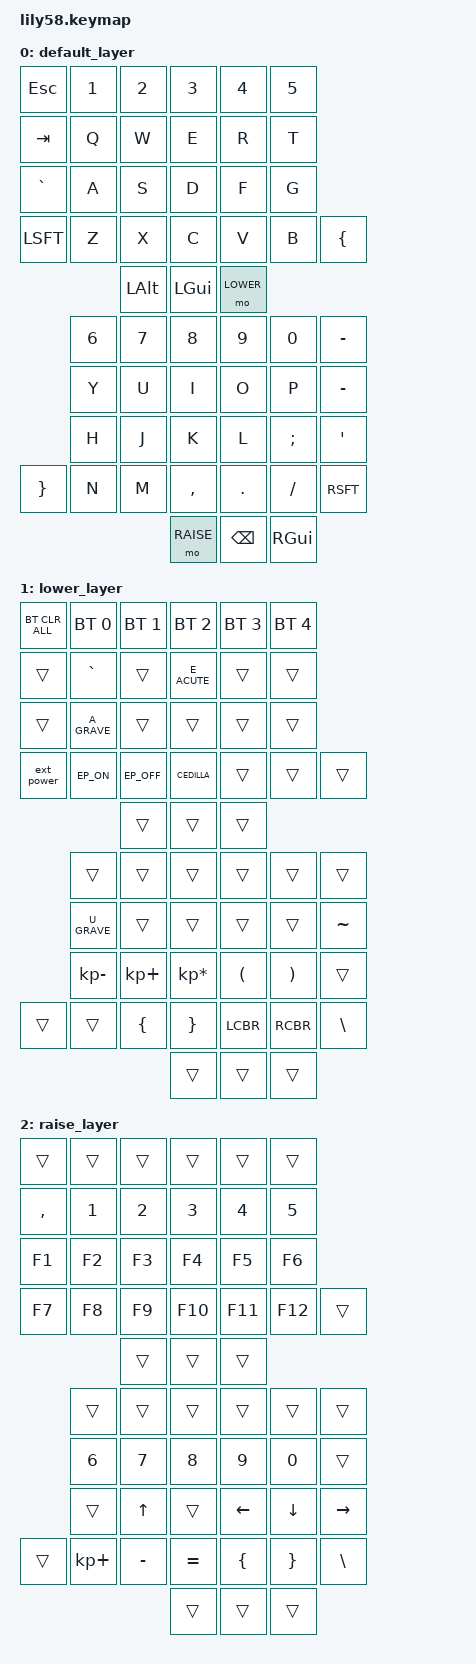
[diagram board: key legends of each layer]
#include <behaviors.dtsi>
#include <dt-bindings/zmk/keys.h>
#include <dt-bindings/zmk/bt.h>
#include <dt-bindings/zmk/ext_power.h>
#include <dt-bindings/zmk/outputs.h>

// Define layer aliases for readability
#define BASE  0
#define LOWER 1
#define RAISE 2

/ {
    keymap {
        compatible = "zmk,keymap";

        // Your exact Base Layer, reconstructed from your image
        default_layer {
            bindings = <
            // Left Hand
            &kp ESC     &kp N1      &kp N2      &kp N3      &kp N4      &kp N5
            &kp TAB     &kp Q       &kp W       &kp E       &kp R       &kp T
            &kp GRAVE   &kp A       &kp S       &kp D       &kp F       &kp G
            &kp LSFT    &kp Z       &kp X       &kp C       &kp V       &kp B       &kp LBRC
                                    &kp LALT    &kp LGUI    &mo LOWER
            // Right Hand
                        &kp N6      &kp N7      &kp N8      &kp N9      &kp N0      &kp MINUS
                        &kp Y       &kp U       &kp I       &kp O       &kp P       &kp MINUS
                        &kp H       &kp J       &kp K       &kp L       &kp SEMI    &kp SQT
            &kp RBRC    &kp N       &kp M       &kp COMMA   &kp DOT     &kp FSLH    &kp RSFT
                                                &mo RAISE   &kp BSPC    &kp RGUI
            >;
        };

        // Your NEW Lower Layer with French Accents
        lower_layer {
            bindings = <
            // Left Hand
            &bt BT_CLR_ALL  &bt BT_SEL 0    &bt BT_SEL 1    &bt BT_SEL 2    &bt BT_SEL 3    &bt BT_SEL 4
            &trans          &kp GRAVE       &trans          &kp E_ACUTE     &trans          &trans
            &trans          &kp A_GRAVE     &trans          &trans          &trans          &trans
            &ext_power      &kp EP_ON       &kp EP_OFF      &kp C_CEDILLA   &trans          &trans          &trans
                                            &trans          &trans          &trans
            // Right Hand
                                            &trans          &trans          &trans          &trans          &trans          &trans
                                            &kp U_GRAVE     &trans          &trans          &trans          &trans          &kp TILDE
                                            &kp KP_MINUS    &kp KP_PLUS     &kp KP_MULTIPLY &kp LPAR        &kp RPAR        &trans
                                            &trans          &trans          &kp LBRC        &kp RBRC        &kp LCBR        &kp RCBR        &kp BSLH
                                                                            &trans          &trans          &trans
            >;
        };


        // Your exact Raise Layer, reconstructed from your image
        raise_layer {
            bindings = <
            // Left Hand
            &trans      &trans      &trans      &trans      &trans      &trans
            &kp COMMA   &kp N1      &kp N2      &kp N3      &kp N4      &kp N5
            &kp F1      &kp F2      &kp F3      &kp F4      &kp F5      &kp F6
            &kp F7      &kp F8      &kp F9      &kp F10     &kp F11     &kp F12     &trans
                                    &trans      &trans      &trans
            // Right Hand
                        &trans      &trans      &trans      &trans      &trans      &trans
                        &kp N6      &kp N7      &kp N8      &kp N9      &kp N0      &trans
                        &trans      &kp UP      &trans      &kp LEFT    &kp DOWN    &kp RIGHT
            &trans      &kp KP_PLUS &kp MINUS   &kp EQUAL   &kp LBRC    &kp RBRC    &kp BSLH
                                                &trans      &trans      &trans
            >;
        };
    };
};
